AUTOSAR XML (schema 00044)
package /VehicleProject
  system System
    system mapping System_MPPNG
      data-mappings:
        data-element=DE_LightSwitch, system-signal=LightSwitch
        data-element=DE_HeadLight, system-signal=HeadLight
    root-software-compositions:
      root sw composition prototype EcuSwComposition: software-composition=ECU_Composition
package /ECUCompositionTypes
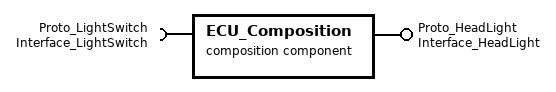
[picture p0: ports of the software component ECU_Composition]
  composition sw component type ECU_Composition
    provide port Proto_HeadLight: nonqueued-sender-com-spec=DE_HeadLight, provided-interface=Interface_HeadLight
    require port Proto_LightSwitch: nonqueued-receiver-com-spec{data-element=DE_LightSwitch, init-value=0}, required-interface=Interface_LightSwitch
    component MySWC: type=MySWC
    delegate MySWC.Proto_HeadLight <-> outer port Proto_HeadLight
    delegate MySWC.Proto_LightSwitch <-> outer port Proto_LightSwitch
package /EndToEndProtections
  end to end protection set EndToEndProtectionSet
